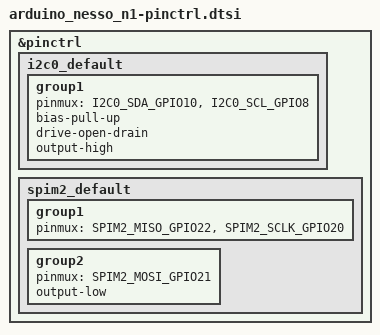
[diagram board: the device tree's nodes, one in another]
/*
 * Copyright (c) 2026 Carlo Caione <ccaione@baylibre.com>
 *
 * SPDX-License-Identifier: Apache-2.0
 */

#include <zephyr/dt-bindings/pinctrl/esp32c6-pinctrl.h>

&pinctrl {
	i2c0_default: i2c0_default {
		group1 {
			pinmux = <I2C0_SDA_GPIO10>,
				 <I2C0_SCL_GPIO8>;
			bias-pull-up;
			drive-open-drain;
			output-high;
		};
	};

	spim2_default: spim2_default {
		group1 {
			pinmux = <SPIM2_MISO_GPIO22>,
				 <SPIM2_SCLK_GPIO20>;
		};

		group2 {
			pinmux = <SPIM2_MOSI_GPIO21>;
			output-low;
		};
	};
};
